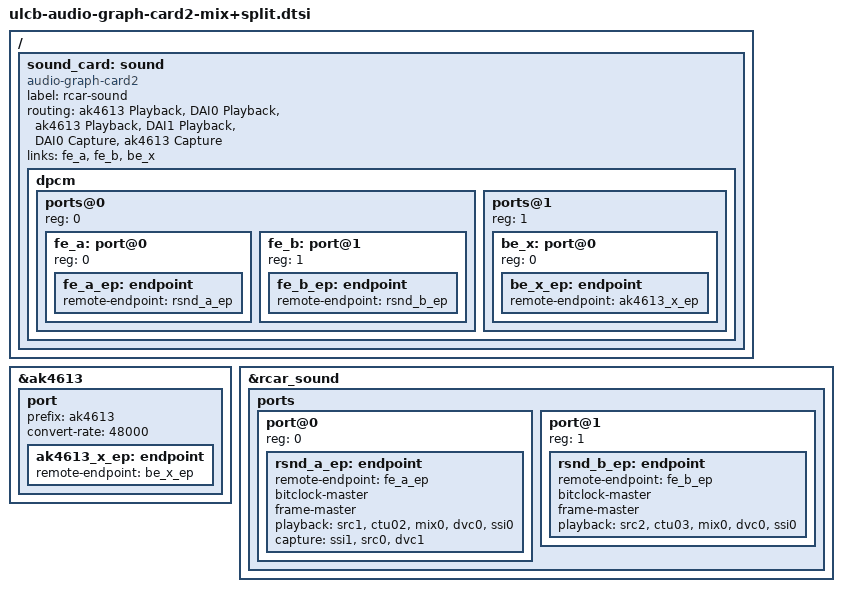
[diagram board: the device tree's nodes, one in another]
/ {
	sound_card: sound {
		compatible = "audio-graph-card2";
		label = "rcar-sound";
		routing = "ak4613 Playback", "DAI0 Playback",
			  "ak4613 Playback", "DAI1 Playback",
			  "DAI0 Capture",    "ak4613 Capture";
		/delete-property/ dais;
		links = <&fe_a		 
			 &fe_b		 
			 &be_x		 
		>;
		dpcm {
			#address-cells = <1>;
			#size-cells = <0>;
			ports@0 {
				#address-cells = <1>;
				#size-cells = <0>;
				reg = <0>;
				fe_a: port@0 { reg = <0>; fe_a_ep: endpoint { remote-endpoint = <&rsnd_a_ep>; }; };
				fe_b: port@1 { reg = <1>; fe_b_ep: endpoint { remote-endpoint = <&rsnd_b_ep>; }; };
			};
			ports@1 {
				#address-cells = <1>;
				#size-cells = <0>;
				reg = <1>;
				be_x: port@0 { reg = <0>; be_x_ep: endpoint { remote-endpoint = <&ak4613_x_ep>; }; };
			};
		};
	};
};
&ak4613 {
	port {
		prefix = "ak4613";
		convert-rate = <48000>;
		ak4613_x_ep: endpoint {
			remote-endpoint = <&be_x_ep>;
		};
	};
};
&rcar_sound {
	ports {
		#address-cells = <1>;
		#size-cells = <0>;
		port@0 {
			reg = <0>;
			rsnd_a_ep: endpoint {
				remote-endpoint = <&fe_a_ep>;
				bitclock-master;
				frame-master;
				playback = <&src1 &ctu02 &mix0 &dvc0 &ssi0>;
				capture  = <&ssi1 &src0 &dvc1>;
			};
		};
		port@1 {
			reg = <1>;
			rsnd_b_ep: endpoint {
				remote-endpoint = <&fe_b_ep>;
				bitclock-master;
				frame-master;
				playback = <&src2 &ctu03 &mix0 &dvc0 &ssi0>;
			};
		};
	};
};
